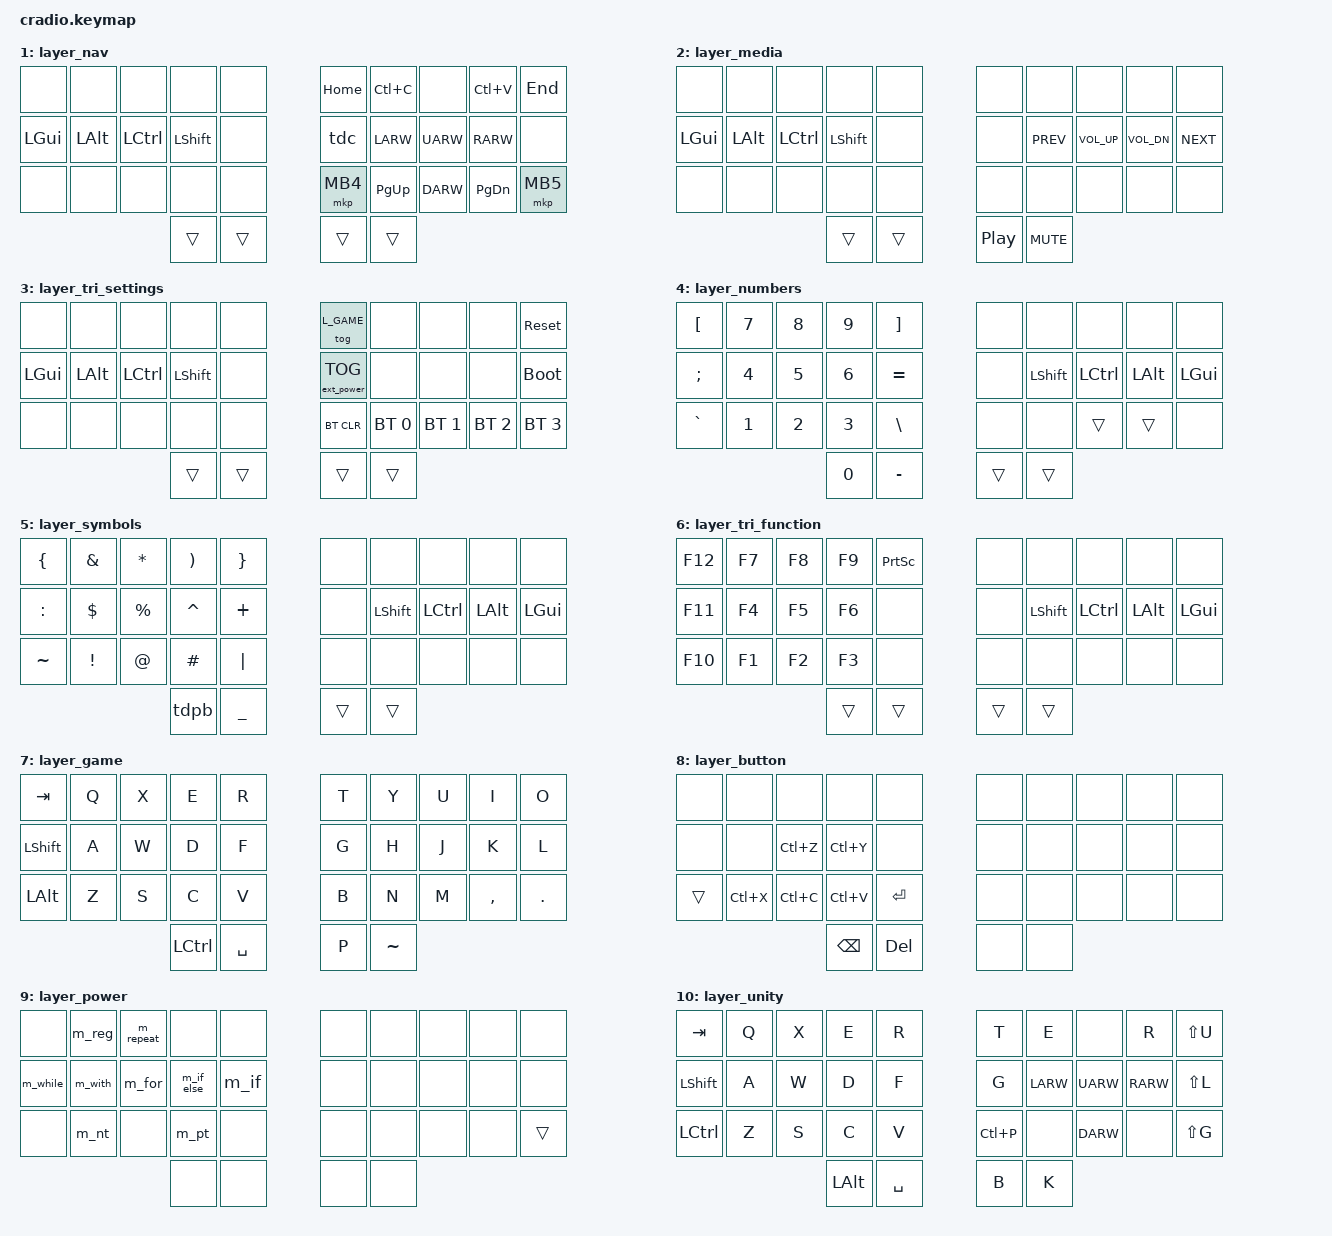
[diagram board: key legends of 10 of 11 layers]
// Copyright (c) 2022 The ZMK Contributors
// SPDX-License-Identifier: MIT

#include <behaviors.dtsi>
#include <dt-bindings/zmk/keys.h>
#include <dt-bindings/zmk/bt.h>
#include <dt-bindings/zmk/mouse.h>
#include <dt-bindings/zmk/ext_power.h>

// Layers
#define L_BASE      0
#define L_NAV       1
#define L_MEDIA     2
#define L_SETTINGS  3
#define L_NUM       4
#define L_SYM       5
#define L_FUN       6
#define L_GAME      7
#define L_BUTTON    8
#define L_POWER     9
#define L_UNITY     10

// Home rows
#define HRML(k1,k2,k3,k4) &phrmt_l LGUI k1   &rmhrmt_l LALT  k2   &rmhrmt_l LCTRL k3   &hrmt_l  LSHFT k4
#define HRMR(k1,k2,k3,k4) &hrmt_r RSHFT k1   &rmhrmt_r RCTRL k2   &rmhrmt_r LALT  k3   &phrmt_r RGUI  k4

// Layer-taps
#define LT_MEDIA    &lt     L_MEDIA     TAB
#define LT_NAV      &lt     L_NAV       SPACE
#define LT_NUM      &bdlt   L_NUM       0
#define LT_SYM      &lt     L_SYM       ENTER
#define LT_BUT      &plt    L_BUTTON    Z
#define LT_POWER    &plt    L_POWER     FSLH

// Layer-toggles
#define TO_UNI      &to  L_UNITY
#define TO_BASE     &to  L_BASE
#define TOG_GAME    &tog L_GAME

// Other
#define POW_TOG &ext_power EP_TOG
#define RIGHT_SIDE  5 6 7 8 9 15 16 17 18 19 25 26 27 28 29 32 33
#define LEFT_SIDE   0 1 2 3 4 10 11 12 13 14 20 21 22 23 24 30 31

&lt {
    tapping-term-ms = <160>;
    quick-tap-ms = <200>;
    require-prior-idle-ms = <50>;
};

&mt {
    tapping-term-ms = <160>;
    quick-tap-ms = <200>;
    require-prior-idle-ms = <50>;
    flavor = "tap-preferred";
};

/ {
    behaviors {

        // Hold-taps

        phrmt_l: pinkie_home_row_mod_tap_left {
            compatible = "zmk,behavior-hold-tap";
            #binding-cells = <2>;
            flavor = "tap-preferred";
            tapping-term-ms = <400>;
            require-prior-idle-ms = <300>;
            hold-trigger-key-positions = <RIGHT_SIDE>;
            hold-trigger-on-release;
            bindings = <&kp>, <&kp>;
        };

        phrmt_r: pinkie_home_row_mod_tap_right {
            compatible = "zmk,behavior-hold-tap";
            #binding-cells = <2>;
            flavor = "tap-preferred";
            tapping-term-ms = <400>;
            require-prior-idle-ms = <300>;
            hold-trigger-key-positions = <LEFT_SIDE>;
            hold-trigger-on-release;
            bindings = <&kp>, <&kp>;
        };

        rmhrmt_r: ring_middle_home_row_mod_tap_right {
            compatible = "zmk,behavior-hold-tap";
            #binding-cells = <2>;
            flavor = "tap-preferred";
            tapping-term-ms = <300>;
            require-prior-idle-ms = <200>;
            hold-trigger-key-positions = <LEFT_SIDE>;
            hold-trigger-on-release;
            bindings = <&kp>, <&kp>;
        };

        rmhrmt_l: ring_middle_home_row_mod_tap_left {
            compatible = "zmk,behavior-hold-tap";
            #binding-cells = <2>;
            flavor = "tap-preferred";
            tapping-term-ms = <300>;
            require-prior-idle-ms = <200>;
            hold-trigger-key-positions = <RIGHT_SIDE>;
            hold-trigger-on-release;
            bindings = <&kp>, <&kp>;
        };

        hrmt_l: home_row_mod_tap_left {
            compatible = "zmk,behavior-hold-tap";
            #binding-cells = <2>;
            flavor = "tap-preferred";
            tapping-term-ms = <160>;
            require-prior-idle-ms = <50>;
            hold-trigger-key-positions = <RIGHT_SIDE>;
            hold-trigger-on-release;
            bindings = <&kp>, <&kp>;
        };

        hrmt_r: home_row_mod_tap_right {
            compatible = "zmk,behavior-hold-tap";
            #binding-cells = <2>;
            flavor = "tap-preferred";
            tapping-term-ms = <160>;
            require-prior-idle-ms = <50>;
            hold-trigger-key-positions = <LEFT_SIDE>;
            hold-trigger-on-release;
            bindings = <&kp>, <&kp>;
        };

        plt: pinkie_layer_tap {
            compatible = "zmk,behavior-hold-tap";
            #binding-cells = <2>;
            flavor = "tap-preferred";
            tapping-term-ms = <250>;
            require-prior-idle-ms = <50>;
            bindings = <&mo>, <&kp>;
        };

        bdlt: backspace_delete_layer_tap {
            compatible = "zmk,behavior-hold-tap";
            #binding-cells = <2>;
            flavor = "tap-preferred";
            tapping-term-ms = <160>;
            require-prior-idle-ms = <50>;
            quick-tap-ms = <200>;
            bindings = <&mo>, <&bd>;
        };

        // Tap-dances

        tdc: tap_dance_caps {
            compatible = "zmk,behavior-tap-dance";
            #binding-cells = <0>;
            tapping-term-ms = <200>;
            bindings = <&caps_word>, <&kp CAPS>;
        };

        tdpb: tap_dance_parenthesis_both {
            compatible = "zmk,behavior-tap-dance";
            #binding-cells = <0>;
            tapping-term-ms = <200>;
            bindings = <&kp LPAR>, <&m_pb>, <&m_pbml>, <&m_pbsc>;
        };

        // Mod-morphs

        bd: backspace_delete {
            compatible = "zmk,behavior-mod-morph";
            #binding-cells = <0>;
            bindings = <&kp BSPC>, <&kp DELETE>;
            mods = <(MOD_LSFT|MOD_RSFT)>;
        };
    };

    macros {
        m_if: macro_if {
            compatible = "zmk,behavior-macro";
            #binding-cells = <0>;
            bindings = <&macro_tap &kp F4 &kp N2>;
        };

        m_if_else: macro_if_else {
            compatible = "zmk,behavior-macro";
            #binding-cells = <0>;
            bindings = <&macro_tap &kp F4 &kp N3>;
        };

        m_for: macro_for {
            compatible = "zmk,behavior-macro";
            #binding-cells = <0>;
            bindings = <&macro_tap &kp F4 &kp N5>;
        };

        m_repeat: macro_repeat {
            compatible = "zmk,behavior-macro";
            #binding-cells = <0>;
            bindings = <&macro_tap &kp F4 &kp N8>;
        };

        m_with: macro_with {
            compatible = "zmk,behavior-macro";
            #binding-cells = <0>;
            bindings = <&macro_tap &kp F4 &kp N0>;
        };

        m_while: macro_while {
            compatible = "zmk,behavior-macro";
            #binding-cells = <0>;
            bindings = <&macro_tap &kp F4 &kp N6>;
        };

        m_reg: macro_region {
            compatible = "zmk,behavior-macro";
            #binding-cells = <0>;
            bindings = <&macro_tap &kp F4 &kp R>;
        };

        m_nt: macro_next_tab {
            compatible = "zmk,behavior-macro";
            #binding-cells = <0>;
            bindings =  <&macro_press &kp LCTRL>,
                        <&macro_tap &kp PG_UP>,
                        <&macro_release &kp LCTRL>;
        };

        m_pt: macro_previous_tab {
            compatible = "zmk,behavior-macro";
            #binding-cells = <0>;
            bindings =  <&macro_press &kp LCTRL>,
                        <&macro_tap &kp PG_DN>,
                        <&macro_release &kp LCTRL>;
        };

        m_pb: macro_parenthesis_both {
            compatible = "zmk,behavior-macro";
            #binding-cells = <0>;
            bindings =  <&macro_tap &kp LPAR &kp RPAR>;
        };

        m_pbml: macro_parenthesis_both_move_left {
            compatible = "zmk,behavior-macro";
            #binding-cells = <0>;
            bindings =  <&macro_tap &kp LPAR &kp RPAR &kp LARW>;
        };

        m_pbsc: macro_parenthesis_both_semicolon {
            compatible = "zmk,behavior-macro";
            #binding-cells = <0>;
            bindings =  <&macro_tap &kp LPAR &kp RPAR &kp SEMICOLON>;
        };
    };

    combos {
        compatible = "zmk,combos";

        combo_esc {
            timeout-ms = <50>;
            require-prior-idle-ms = <100>;
            key-positions = <0 1>;
            bindings = <&kp ESC>;
        };

        combo_to_uni_left {
            timeout-ms = <50>;
            require-prior-idle-ms = <200>;
            key-positions = <12 31>;
            layers = <0 10>;
            bindings = <TO_UNI>;
        };

        combo_to_base_left {
            timeout-ms = <50>;
            require-prior-idle-ms = <200>;
            key-positions = <13 31>;
            layers = <0 10>;
            bindings = <TO_BASE>;
        };

        combo_to_uni_right {
            timeout-ms = <50>;
            require-prior-idle-ms = <200>;
            key-positions = <17 32>;
            layers = <0 10>;
            bindings = <TO_UNI>;
        };

        combo_to_base_right {
            timeout-ms = <50>;
            require-prior-idle-ms = <200>;
            key-positions = <16 32>;
            layers = <0 10>;
            bindings = <TO_BASE>;
        };

        combo_to_game_jank {
            timeout-ms = <50>;
            require-prior-idle-ms = <200>;
            key-positions = <0 4>;
            layers = <0 7>;
            bindings = <TOG_GAME>;
        };
    };

    conditional_layers {
        compatible = "zmk,conditional-layers";

        layer_tri_settings {
            if-layers = <L_NAV L_MEDIA>;
            then-layer = <L_SETTINGS>;
        };

        layer_tri_function {
            if-layers = <L_NUM L_SYM>;
            then-layer = <L_FUN>;
        };
    };

    keymap {
        compatible = "zmk,keymap";
        layer_base {
            bindings = <
        //╭──────────┬──────────┬──────────┬──────────┬──────────╮   ╭──────────┬──────────┬──────────┬──────────┬──────────╮
            &kp Q      &kp W      &kp E      &kp R      &kp T          &kp Y      &kp U      &kp I      &kp O      &kp P
        //├──────────┼──────────┼──────────┼──────────┼──────────┤   ├──────────┼──────────┼──────────┼──────────┼──────────┤
            HRML(A,        S,         D,         F)     &kp G          &kp H      HRMR(J,        K,         L,        SQT)
        //├──────────┼──────────┼──────────┼──────────┼──────────┤   ├──────────┼──────────┼──────────┼──────────┼──────────┤
            LT_BUT     &mt RALT X &kp C      &kp V      &kp B          &kp N      &kp M      &kp COMMA &mt RALT DOT LT_POWER
        //╰──────────┴──────────┴──────────┼──────────┼──────────┤   ├──────────┼──────────┼──────────┴──────────┴──────────╯
                                             LT_MEDIA   LT_NAV         LT_SYM     LT_NUM
        //                                 ╰──────────┴──────────╯   ╰──────────┴──────────╯
            >;
        };

        layer_nav {
            bindings = <
        //╭──────────┬──────────┬──────────┬──────────┬──────────╮   ╭──────────┬──────────┬──────────┬──────────┬──────────╮
            &none      &none      &none      &none      &none          &kp HOME   &kp LC(C)  &none      &kp LC(V)  &kp END
        //├──────────┼──────────┼──────────┼──────────┼──────────┤   ├──────────┼──────────┼──────────┼──────────┼──────────┤
            &kp LGUI   &kp LALT   &kp LCTRL  &kp LSHFT  &none          &tdc       &kp LARW   &kp UARW   &kp RARW   &none
        //├──────────┼──────────┼──────────┼──────────┼──────────┤   ├──────────┼──────────┼──────────┼──────────┼──────────┤
            &none      &none      &none      &none      &none          &mkp MB4   &kp PG_UP  &kp DARW   &kp PG_DN  &mkp MB5
        //╰──────────┴──────────┴──────────┼──────────┼──────────┤   ├──────────┼──────────┼──────────┴──────────┴──────────╯
                                             &trans     &trans         &trans     &trans
        //                                 ╰──────────┴──────────╯   ╰──────────┴──────────╯
            >;
        };

        layer_media {
            bindings = <
        //╭──────────┬──────────┬──────────┬──────────┬──────────╮   ╭──────────┬──────────┬──────────┬──────────┬──────────╮
            &none      &none      &none      &none      &none          &none      &none      &none      &none      &none
        //├──────────┼──────────┼──────────┼──────────┼──────────┤   ├──────────┼──────────┼──────────┼──────────┼──────────┤
            &kp LGUI   &kp LALT   &kp LCTRL  &kp LSHFT  &none          &none    &kp C_PREV &kp C_VOL_UP &kp C_VOL_DN &kp C_NEXT
        //├──────────┼──────────┼──────────┼──────────┼──────────┤   ├──────────┼──────────┼──────────┼──────────┼──────────┤
            &none     &none       &none      &none      &none          &none      &none      &none      &none      &none
        //╰──────────┴──────────┴──────────┼──────────┼──────────┤   ├──────────┼──────────┼──────────┴──────────┴──────────╯
                                             &trans     &trans         &kp C_PP   &kp C_MUTE
        //                                 ╰──────────┴──────────╯   ╰──────────┴──────────╯
            >;
        };

        layer_tri_settings {
            bindings = <
        //╭──────────┬──────────┬──────────┬──────────┬──────────╮   ╭──────────┬──────────┬──────────┬──────────┬──────────╮
            &none      &none      &none      &none      &none          TOG_GAME   &none      &none      &none      &sys_reset
        //├──────────┼──────────┼──────────┼──────────┼──────────┤   ├──────────┼──────────┼──────────┼──────────┼──────────┤
            &kp LGUI   &kp LALT   &kp LCTRL  &kp LSHFT  &none          POW_TOG    &none      &none      &none      &bootloader
        //├──────────┼──────────┼──────────┼──────────┼──────────┤   ├──────────┼──────────┼──────────┼──────────┼──────────┤
            &none      &none      &none      &none      &none         &bt BT_CLR &bt BT_SEL 0 &bt BT_SEL 1 &bt BT_SEL 2 &bt BT_SEL 3 
        //╰──────────┴──────────┴──────────┼──────────┼──────────┤   ├──────────┼──────────┼──────────┴──────────┴──────────╯
                                             &trans     &trans         &trans     &trans
        //                                 ╰──────────┴──────────╯   ╰──────────┴──────────╯
            >;
        };

        layer_numbers {
            bindings = <
        //╭──────────┬──────────┬──────────┬──────────┬──────────╮   ╭──────────┬──────────┬──────────┬──────────┬──────────╮
            &kp LBKT   &kp N7     &kp N8     &kp N9     &kp RBKT       &none      &none      &none      &none      &none
        //├──────────┼──────────┼──────────┼──────────┼──────────┤   ├──────────┼──────────┼──────────┼──────────┼──────────┤
            &kp SEMI   &kp N4     &kp N5     &kp N6     &kp EQUAL      &none      &kp LSHFT  &kp LCTRL  &kp LALT   &kp LGUI
        //├──────────┼──────────┼──────────┼──────────┼──────────┤   ├──────────┼──────────┼──────────┼──────────┼──────────┤
            &kp GRAVE  &kp N1     &kp N2     &kp N3     &kp BSLH       &none      &none      &trans     &trans     &none
        //╰──────────┴──────────┴──────────┼──────────┼──────────┤   ├──────────┼──────────┼──────────┴──────────┴──────────╯
                                             &kp N0     &kp MINUS      &trans     &trans
        //                                 ╰──────────┴──────────╯   ╰──────────┴──────────╯
            >;
        };

        layer_symbols {
            bindings = <
        //╭──────────┬──────────┬──────────┬──────────┬──────────╮   ╭──────────┬──────────┬──────────┬──────────┬──────────╮
            &kp LBRC   &kp AMPS   &kp STAR   &kp RPAR   &kp RBRC       &none      &none      &none      &none      &none
        //├──────────┼──────────┼──────────┼──────────┼──────────┤   ├──────────┼──────────┼──────────┼──────────┼──────────┤
            &kp COLON  &kp DLLR   &kp PRCNT  &kp CARET  &kp PLUS       &none      &kp LSHFT  &kp LCTRL  &kp LALT   &kp LGUI
        //├──────────┼──────────┼──────────┼──────────┼──────────┤   ├──────────┼──────────┼──────────┼──────────┼──────────┤
            &kp TILDE  &kp EXCL   &kp AT     &kp POUND  &kp PIPE       &none      &none      &none      &none      &none
        //╰──────────┴──────────┴──────────┼──────────┼──────────┤   ├──────────┼──────────┼──────────┴──────────┴──────────╯
                                             &tdpb      &kp UNDER      &trans     &trans
        //                                 ╰──────────┴──────────╯   ╰──────────┴──────────╯
            >;
        };

        layer_tri_function {
            bindings = <
        //╭──────────┬──────────┬──────────┬──────────┬──────────╮   ╭──────────┬──────────┬──────────┬──────────┬──────────╮
            &kp F12    &kp F7     &kp F8     &kp F9     &kp PSCRN      &none      &none      &none      &none      &none
        //├──────────┼──────────┼──────────┼──────────┼──────────┤   ├──────────┼──────────┼──────────┼──────────┼──────────┤
            &kp F11    &kp F4     &kp F5     &kp F6     &none          &none      &kp LSHFT  &kp LCTRL  &kp LALT   &kp LGUI
        //├──────────┼──────────┼──────────┼──────────┼──────────┤   ├──────────┼──────────┼──────────┼──────────┼──────────┤
            &kp F10    &kp F1     &kp F2     &kp F3     &none          &none      &none      &none      &none      &none
        //╰──────────┴──────────┴──────────┼──────────┼──────────┤   ├──────────┼──────────┼──────────┴──────────┴──────────╯
                                             &trans     &trans         &trans     &trans
        //                                 ╰──────────┴──────────╯   ╰──────────┴──────────╯
            >;
        };

        layer_game {
            bindings = <
        //╭──────────┬──────────┬──────────┬──────────┬──────────╮   ╭──────────┬──────────┬──────────┬──────────┬──────────╮
            &kp TAB    &kp Q      &kp X      &kp E      &kp R          &kp T      &kp Y      &kp U      &kp I      &kp O
        //├──────────┼──────────┼──────────┼──────────┼──────────┤   ├──────────┼──────────┼──────────┼──────────┼──────────┤
            &kp LSHFT  &kp A      &kp W      &kp D      &kp F          &kp G      &kp H      &kp J      &kp K      &kp L
        //├──────────┼──────────┼──────────┼──────────┼──────────┤   ├──────────┼──────────┼──────────┼──────────┼──────────┤
            &kp LALT   &kp Z      &kp S      &kp C      &kp V          &kp B      &kp N      &kp M      &kp COMMA  &kp DOT
        //╰──────────┴──────────┴──────────┼──────────┼──────────┤   ├──────────┼──────────┼──────────┴──────────┴──────────╯
                                             &kp LCTRL  &kp SPACE      &kp P      &kp TILDE
        //                                 ╰──────────┴──────────╯   ╰──────────┴──────────╯
            >;
        };

        layer_button {
            bindings = <
        //╭──────────┬──────────┬──────────┬──────────┬──────────╮   ╭──────────┬──────────┬──────────┬──────────┬──────────╮
            &none      &none      &none      &none      &none          &none      &none      &none      &none      &none
        //├──────────┼──────────┼──────────┼──────────┼──────────┤   ├──────────┼──────────┼──────────┼──────────┼──────────┤
            &none      &none      &kp LC(Z)  &kp LC(Y)  &none          &none      &none      &none      &none      &none
        //├──────────┼──────────┼──────────┼──────────┼──────────┤   ├──────────┼──────────┼──────────┼──────────┼──────────┤
            &trans     &kp LC(X)  &kp LC(C)  &kp LC(V)  &kp ENTER      &none      &none      &none      &none      &none
        //╰──────────┴──────────┴──────────┼──────────┼──────────┤   ├──────────┼──────────┼──────────┴──────────┴──────────╯
                                             &kp BSPC   &kp DEL        &none      &none
        //                                 ╰──────────┴──────────╯   ╰──────────┴──────────╯
            >;
        };

        layer_power {
            bindings = <
        //╭──────────┬──────────┬──────────┬──────────┬──────────╮   ╭──────────┬──────────┬──────────┬──────────┬──────────╮
            &none      &m_reg     &m_repeat  &none      &none          &none      &none      &none      &none      &none
        //├──────────┼──────────┼──────────┼──────────┼──────────┤   ├──────────┼──────────┼──────────┼──────────┼──────────┤
            &m_while   &m_with    &m_for     &m_if_else &m_if          &none      &none      &none      &none      &none          
        //├──────────┼──────────┼──────────┼──────────┼──────────┤   ├──────────┼──────────┼──────────┼──────────┼──────────┤
            &none      &m_nt      &none      &m_pt      &none          &none      &none      &none      &none      &trans
        //╰──────────┴──────────┴──────────┼──────────┼──────────┤   ├──────────┼──────────┼──────────┴──────────┴──────────╯
                                             &none      &none          &none      &none
        //                                 ╰──────────┴──────────╯   ╰──────────┴──────────╯
            >;
        };

        layer_unity {
            bindings = <
        //╭──────────┬──────────┬──────────┬──────────┬──────────╮   ╭──────────┬──────────┬──────────┬──────────┬──────────╮
            &kp TAB    &kp Q      &kp X      &kp E      &kp R          &kp T      &kp E      &none      &kp R      &kp LS(U)
        //├──────────┼──────────┼──────────┼──────────┼──────────┤   ├──────────┼──────────┼──────────┼──────────┼──────────┤
            &kp LSHFT  &kp A      &kp W      &kp D      &kp F          &kp G      &kp LARW   &kp UARW   &kp RARW   &kp LS(L)
        //├──────────┼──────────┼──────────┼──────────┼──────────┤   ├──────────┼──────────┼──────────┼──────────┼──────────┤
            &kp LCTRL  &kp Z      &kp S      &kp C      &kp V          &kp LC(P)  &none      &kp DARW   &none      &kp LS(G)
        //╰──────────┴──────────┴──────────┼──────────┼──────────┤   ├──────────┼──────────┼──────────┴──────────┴──────────╯
                                             &kp LALT   &kp SPACE      &kp B      &kp K
        //                                 ╰──────────┴──────────╯   ╰──────────┴──────────╯
            >;
        };
    };
};
